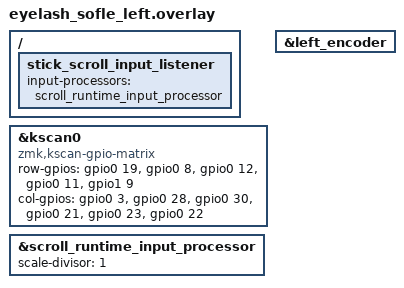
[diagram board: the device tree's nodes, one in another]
/*
*
* Copyright (c) 2021 Darryl deHaan
* SPDX-License-Identifier: MIT
*
*/

#include "eyelash_sofle.dtsi"
#include <behaviors/battery_history_request.dtsi>
#include <input/processors.dtsi>
#include <input/processors/runtime-input-processor.dtsi>

&kscan0 {
    compatible = "zmk,kscan-gpio-matrix";
    row-gpios
        = <&gpio0 19 (GPIO_ACTIVE_HIGH | GPIO_PULL_DOWN)>
        , <&gpio0 8 (GPIO_ACTIVE_HIGH | GPIO_PULL_DOWN)>
        , <&gpio0 12 (GPIO_ACTIVE_HIGH | GPIO_PULL_DOWN)>
        , <&gpio0 11 (GPIO_ACTIVE_HIGH | GPIO_PULL_DOWN)>
        , <&gpio1 9 (GPIO_ACTIVE_HIGH | GPIO_PULL_DOWN)>
        ;
    col-gpios
        = <&gpio0 3 GPIO_ACTIVE_HIGH>
        , <&gpio0 28 GPIO_ACTIVE_HIGH>
        , <&gpio0 30 GPIO_ACTIVE_HIGH>
        , <&gpio0 21 GPIO_ACTIVE_HIGH>
        , <&gpio0 23 GPIO_ACTIVE_HIGH>
        , <&gpio0 22 GPIO_ACTIVE_HIGH>
        ;
};

&left_encoder {
    status = "okay";
};

/ {
    // Joystick scrolling (layers 1 and 2). Merged by path into the listener the keymap defines,
    // because the keymap is applied after this overlay. Speed multiplier is adjustable without
    // reflashing in DYA Studio or https://cormoran.github.io/zmk-module-runtime-input-processor/
    stick_scroll_input_listener {
        input-processors = <&scroll_runtime_input_processor>;
    };
};

// The module's default scroll scale (1/60) is meant for trackballs; start at 1:1.
&scroll_runtime_input_processor {
    scale-divisor = <1>;
};
